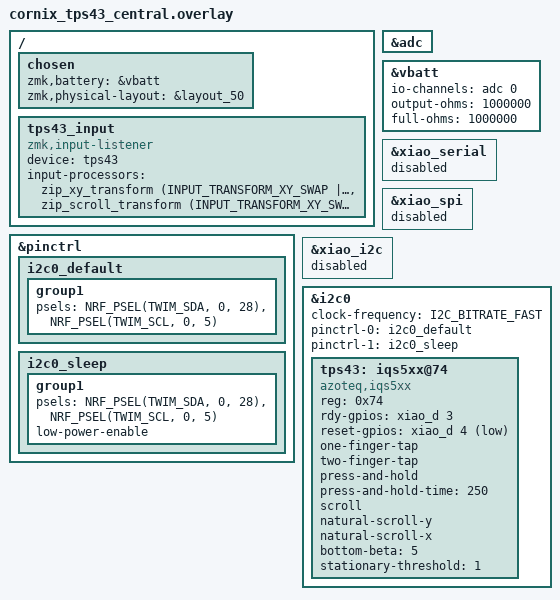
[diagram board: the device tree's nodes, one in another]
#include <dt-bindings/gpio/gpio.h>
#include <dt-bindings/i2c/i2c.h>
#include <dt-bindings/input/input-event-codes.h>
#include <dt-bindings/zmk/input_transform.h>
#include <input/processors.dtsi>
#include "../../jzf/cornix/cornix_dongle_common.dtsi"

/ {
    chosen {
        zmk,battery = &vbatt;
        zmk,physical-layout = &layout_50;
    };

    tps43_input: tps43_input {
        compatible = "zmk,input-listener";
        device = <&tps43>;
        /* TPS43 is mounted 90 degrees clockwise in the Cornix enclosure.
         * Convert sensor coordinates back to screen coordinates:
         * screen X = -sensor Y, screen Y = -sensor X.
         */
        input-processors =
            <&zip_xy_transform
                (INPUT_TRANSFORM_XY_SWAP | INPUT_TRANSFORM_X_INVERT | INPUT_TRANSFORM_Y_INVERT)>,
            <&zip_scroll_transform
                (INPUT_TRANSFORM_XY_SWAP | INPUT_TRANSFORM_X_INVERT | INPUT_TRANSFORM_Y_INVERT)>;
    };
};

&pinctrl {
    i2c0_default: i2c0_default {
        group1 {
            psels = <NRF_PSEL(TWIM_SDA, 0,  28)>,
                    <NRF_PSEL(TWIM_SCL, 0,  5)>;
        };
    };

    i2c0_sleep: i2c0_sleep {
        group1 {
            psels = <NRF_PSEL(TWIM_SDA, 0,  28)>,
                    <NRF_PSEL(TWIM_SCL, 0,  5)>;
            low-power-enable;
        };
    };
};

&adc {
    status = "okay";
};

/* Cornix has its own A0 divider; override the XIAO ZMK board default. */
&vbatt {
    io-channels = <&adc 0>;
    /delete-property/ power-gpios;
    output-ohms = <1000000>;
    full-ohms = <1000000>;
};

/*
 * The TPS43 shield owns the relevant connector pins through i2c0 and its
 * GPIOs. Disable the unused XIAO defaults so they cannot reserve the same
 * pins before the shield is initialized.
 */
&xiao_serial {
    status = "disabled";
};

&xiao_spi {
    status = "disabled";
};

&xiao_i2c {
    status = "disabled";
};

&i2c0 {
    status = "okay";
    clock-frequency = <I2C_BITRATE_FAST>;
    pinctrl-0 = <&i2c0_default>;
    pinctrl-1 = <&i2c0_sleep>;
    pinctrl-names = "default", "sleep";

    tps43: iqs5xx@74 {
        compatible = "azoteq,iqs5xx";
        reg = <0x74>;
        status = "okay";

        /* TPS43 FPC: RDY -> D3, NRST -> D2, SDA/SCL -> XIAO I2C D4/D5. */
        rdy-gpios = <&xiao_d 3 GPIO_ACTIVE_HIGH>;
        reset-gpios = <&xiao_d 4 GPIO_ACTIVE_LOW>;

        one-finger-tap;
        two-finger-tap;
        press-and-hold;
        press-and-hold-time = <250>;
        scroll;
        natural-scroll-y;
        natural-scroll-x;

        bottom-beta = <5>;
        /* Preserve low-speed motion instead of quantizing it into visible steps. */
        stationary-threshold = <1>;
    };
};
